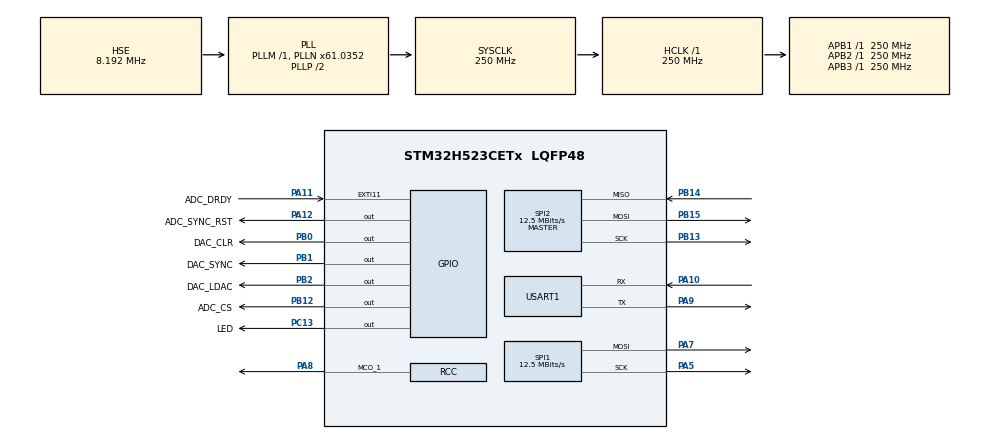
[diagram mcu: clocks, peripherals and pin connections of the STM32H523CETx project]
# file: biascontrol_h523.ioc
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BOOTPATH.BootPathName=LEGACY
BOOTPATH.UserSelectedBootPath=LEGACY
CORTEX_M33_NS.Number-Cortex_Memory_Protection_Unit_Region0_OTP_RO_AREAS_Settings=MPU_REGION_NUMBER0
CORTEX_M33_NS.default_mode_Activation=1
CORTEX_M33_NS.userName=CORTEX_M33
GPDMA1.CIRCULARMODE_GPDMACH4=ENABLE
GPDMA1.DESTINC_GPDMACH2=DMA_DINC_INCREMENTED
GPDMA1.DESTINC_GPDMACH4=DMA_DINC_INCREMENTED
GPDMA1.DIRECTION_GPDMACH0=DMA_MEMORY_TO_PERIPH
GPDMA1.DIRECTION_GPDMACH1=DMA_MEMORY_TO_PERIPH
GPDMA1.DIRECTION_GPDMACH3=DMA_MEMORY_TO_PERIPH
GPDMA1.IPHANDLE_GPDMACH0-SIMPLEREQUEST_GPDMACH0=__NULL
GPDMA1.IPHANDLE_GPDMACH1-SIMPLEREQUEST_GPDMACH1=__NULL
GPDMA1.IPHANDLE_GPDMACH2-SIMPLEREQUEST_GPDMACH2=__NULL
GPDMA1.IPHANDLE_GPDMACH3-SIMPLEREQUEST_GPDMACH3=__NULL
GPDMA1.IPHANDLE_GPDMACH4-SIMPLEREQUEST_GPDMACH4=__NULL
GPDMA1.LINKALLOCATEDPORT_CIRCULAR_GPDMACH4=DMA_LINK_ALLOCATED_PORT1
GPDMA1.REQUEST_GPDMACH0=GPDMA1_REQUEST_SPI1_TX
GPDMA1.REQUEST_GPDMACH1=GPDMA1_REQUEST_SPI2_TX
GPDMA1.REQUEST_GPDMACH2=GPDMA1_REQUEST_SPI2_RX
GPDMA1.REQUEST_GPDMACH3=GPDMA1_REQUEST_USART1_TX
GPDMA1.REQUEST_GPDMACH4=GPDMA1_REQUEST_USART1_RX
GPDMA1.SRCINC_GPDMACH0=DMA_SINC_INCREMENTED
GPDMA1.SRCINC_GPDMACH1=DMA_SINC_INCREMENTED
GPDMA1.SRCINC_GPDMACH3=DMA_SINC_INCREMENTED
GPDMA1.TRANSFERALLOCATEDPORTDEST_GPDMACH2=DMA_DEST_ALLOCATED_PORT1
GPDMA1.TRANSFERALLOCATEDPORTDEST_GPDMACH4=DMA_DEST_ALLOCATED_PORT1
GPDMA1.TRANSFERALLOCATEDPORTSRC_GPDMACH0=DMA_SRC_ALLOCATED_PORT1
GPDMA1.TRANSFERALLOCATEDPORTSRC_GPDMACH1=DMA_SRC_ALLOCATED_PORT1
GPDMA1.TRANSFERALLOCATEDPORTSRC_GPDMACH3=DMA_SRC_ALLOCATED_PORT1
Mcu.Family=STM32H5
Mcu.Name=STM32H523CETx
Mcu.Package=LQFP48
NVIC.EXTI11_IRQn=true\:0\:0\:false\:false\:true\:true\:true\:true
NVIC.GPDMA1_Channel0_IRQn=true\:3\:0\:true\:false\:true\:false\:true\:true
NVIC.GPDMA1_Channel1_IRQn=true\:2\:0\:true\:false\:true\:false\:true\:true
NVIC.GPDMA1_Channel2_IRQn=true\:2\:0\:true\:false\:true\:false\:true\:true
NVIC.GPDMA1_Channel3_IRQn=true\:5\:0\:true\:false\:true\:false\:true\:true
NVIC.GPDMA1_Channel4_IRQn=true\:5\:0\:true\:false\:true\:false\:true\:true
NVIC.PriorityGroup=NVIC_PRIORITYGROUP_4
NVIC.SPI1_IRQn=true\:4\:0\:true\:false\:true\:true\:true\:true
NVIC.SPI2_IRQn=true\:2\:0\:true\:false\:true\:true\:true\:true
NVIC.TIM6_IRQn=true\:6\:0\:true\:false\:true\:true\:true\:true
NVIC.USART1_IRQn=true\:5\:0\:true\:false\:true\:false\:true\:true
PA10.Mode=Asynchronous
PA10.Signal=USART1_RX
PA11.GPIO_Label=ADC_DRDY
PA11.GPIO_ModeDefaultEXTI=GPIO_MODE_IT_FALLING
PA11.GPIO_PuPd=GPIO_PULLUP
PA11.Signal=GPXTI11
PA12.GPIO_Label=ADC_SYNC_RST
PA12.GPIO_Speed=GPIO_SPEED_FREQ_VERY_HIGH
PA12.PinState=GPIO_PIN_SET
PA12.Signal=GPIO_Output
PA13(JTMS/SWDIO).Mode=Serial_Wire
PA13(JTMS/SWDIO).Signal=DEBUG_JTMS-SWDIO
PA14(JTCK/SWCLK).Mode=Serial_Wire
PA14(JTCK/SWCLK).Signal=DEBUG_JTCK-SWCLK
PA5.GPIO_Speed=GPIO_SPEED_FREQ_VERY_HIGH
PA5.Mode=TX_Only_Simplex_Unidirect_Master
PA5.Signal=SPI1_SCK
PA7.GPIO_Speed=GPIO_SPEED_FREQ_VERY_HIGH
PA7.Mode=TX_Only_Simplex_Unidirect_Master
PA7.Signal=SPI1_MOSI
PA8.Mode=Clock-out
PA8.Signal=RCC_MCO_1
PA9.Mode=Asynchronous
PA9.Signal=USART1_TX
PB0.GPIO_Label=DAC_CLR
PB0.GPIO_Speed=GPIO_SPEED_FREQ_VERY_HIGH
PB0.PinState=GPIO_PIN_SET
PB0.Signal=GPIO_Output
PB1.GPIO_Label=DAC_SYNC
PB1.GPIO_Speed=GPIO_SPEED_FREQ_VERY_HIGH
PB1.PinState=GPIO_PIN_SET
PB1.Signal=GPIO_Output
PB12.GPIO_Label=ADC_CS
PB12.GPIO_Speed=GPIO_SPEED_FREQ_VERY_HIGH
PB12.PinState=GPIO_PIN_SET
PB12.Signal=GPIO_Output
PB13.GPIO_Speed=GPIO_SPEED_FREQ_VERY_HIGH
PB13.Mode=Full_Duplex_Master
PB13.Signal=SPI2_SCK
PB14.GPIO_Speed=GPIO_SPEED_FREQ_VERY_HIGH
PB14.Mode=Full_Duplex_Master
PB14.Signal=SPI2_MISO
PB15.GPIO_Speed=GPIO_SPEED_FREQ_VERY_HIGH
PB15.Mode=Full_Duplex_Master
PB15.Signal=SPI2_MOSI
PB2.GPIO_Label=DAC_LDAC
PB2.GPIO_Speed=GPIO_SPEED_FREQ_VERY_HIGH
PB2.PinState=GPIO_PIN_SET
PB2.Signal=GPIO_Output
PC13.GPIO_Label=LED
PC13.Signal=GPIO_Output
PH0-OSC_IN(PH0).Mode=HSE-External-Oscillator
PH0-OSC_IN(PH0).Signal=RCC_OSC_IN
PH1-OSC_OUT(PH1).Mode=HSE-External-Oscillator
PH1-OSC_OUT(PH1).Signal=RCC_OSC_OUT
ProjectManager.HeapSize=0x800
ProjectManager.StackSize=0x1000
ProjectManager.TargetToolchain=Makefile
RCC.ADCFreq_Value=250000000
RCC.AHBFreq_Value=250000000
RCC.APB1Freq_Value=250000000
RCC.APB1TimFreq_Value=250000000
RCC.APB2Freq_Value=250000000
RCC.APB2TimFreq_Value=250000000
RCC.APB3Freq_Value=250000000
RCC.CSI_VALUE=4000000
RCC.CortexFreq_Value=250000000
RCC.EPOD_VALUE=8192000
RCC.HCLKFreq_Value=250000000
RCC.HSE_VALUE=8192000
RCC.HSI48_VALUE=48000000
RCC.HSI_VALUE=64000000
RCC.LSE_VALUE=32768
RCC.LSIRC_VALUE=32000
RCC.PLL1Q=5
RCC.PLL2Source=RCC_PLL2_SOURCE_HSE
RCC.PLL3Source=RCC_PLL3_SOURCE_HSE
RCC.PLLFRACN=288
RCC.PLLN=61
RCC.PLLSourceVirtual=RCC_PLL1_SOURCE_HSE
RCC.RCC_MCO1Source=RCC_MCO1SOURCE_HSE
RCC.SYSCLKFreq_VALUE=250000000
RCC.SYSCLKSource=RCC_SYSCLKSOURCE_PLLCLK
RCC.USBFreq_Value=48000000
RCC.VCOOutputFreq_Value=500000000
SPI1.BaudRatePrescaler=SPI_BAUDRATEPRESCALER_8
SPI1.CLKPhase=SPI_PHASE_2EDGE
SPI1.CalculateBaudRate=12.5 MBits/s
SPI1.DataSize=SPI_DATASIZE_8BIT
SPI1.Direction=SPI_DIRECTION_2LINES_TXONLY
SPI1.Mode=SPI_MODE_MASTER
SPI1.VirtualType=VM_MASTER
SPI2.BaudRatePrescaler=SPI_BAUDRATEPRESCALER_8
SPI2.CLKPhase=SPI_PHASE_2EDGE
SPI2.CalculateBaudRate=12.5 MBits/s
SPI2.DataSize=SPI_DATASIZE_8BIT
SPI2.Direction=SPI_DIRECTION_2LINES
SPI2.Mode=SPI_MODE_MASTER
SPI2.VirtualType=VM_MASTER
TIM6.AutoReloadPreload=TIM_AUTORELOAD_PRELOAD_ENABLE
TIM6.PeriodNoDither=999
TIM6.Prescaler=2499
USART1.VirtualMode-Asynchronous=VM_ASYNC
VP_BOOTPATH_VS_BOOTPATH.Mode=BP_Activate
VP_CORTEX_M33_NS_VS_Hclk.Mode=Hclk_Mode
VP_GPDMA1_VS_GPDMACH0.Mode=SIMPLEREQUEST_GPDMACH0
VP_GPDMA1_VS_GPDMACH1.Mode=SIMPLEREQUEST_GPDMACH1
VP_GPDMA1_VS_GPDMACH2.Mode=SIMPLEREQUEST_GPDMACH2
VP_GPDMA1_VS_GPDMACH3.Mode=SIMPLEREQUEST_GPDMACH3
VP_GPDMA1_VS_GPDMACH4.Mode=SIMPLEREQUEST_GPDMACH4
VP_ICACHE_VS_ICACHE.Mode=DirectMappedCache
VP_MEMORYMAP_VS_MEMORYMAP.Mode=CurAppReg
VP_PWR_VS_LPOM.Mode=PowerOptimisation
VP_PWR_VS_SECSignals.Mode=Security/Privilege
VP_TIM6_VS_ClockSourceINT.Mode=Enable_Timer
board=custom

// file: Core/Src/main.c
/* USER CODE BEGIN Header */
/**
  ******************************************************************************
  * @file           : main.c
  * @brief          : Main program body
  ******************************************************************************
  * @attention
  *
  * Copyright (c) 2026 STMicroelectronics.
  * All rights reserved.
  *
  * This software is licensed under terms that can be found in the LICENSE file
  * in the root directory of this software component.
  * If no LICENSE file comes with this software, it is provided AS-IS.
  *
  ******************************************************************************
  */
/* USER CODE END Header */
#include "main.h"
#include "gpdma.h"
#include "icache.h"
#include "spi.h"
#include "tim.h"
#include "usart.h"
#include "gpio.h"

/* USER CODE BEGIN Includes */
#include "app_main.h"
/* USER CODE END Includes */

void SystemClock_Config(void);
static void MPU_Config(void);

int main(void)
{

  /* MCU Configuration--------------------------------------------------------*/

  /* MPU Configuration--------------------------------------------------------*/
  MPU_Config();

  /* Reset of all peripherals, Initializes the Flash interface and the Systick. */
  HAL_Init();

  /* Configure the system clock */
  SystemClock_Config();

  /* Initialize all configured peripherals */
  MX_GPIO_Init();
  MX_GPDMA1_Init();
  MX_ICACHE_Init();
  MX_SPI1_Init();
  MX_SPI2_Init();
  MX_TIM6_Init();
  MX_USART1_UART_Init();
  /* USER CODE BEGIN 2 */
  app_init();
  /* USER CODE END 2 */

  /* Infinite loop */
  while (1)
  {

    /* USER CODE BEGIN 3 */
    app_run();
    __WFI();
  }
  /* USER CODE END 3 */
}

void SystemClock_Config(void)
{
  RCC_OscInitTypeDef RCC_OscInitStruct = {0};
  RCC_ClkInitTypeDef RCC_ClkInitStruct = {0};

  /** Configure the main internal regulator output voltage
  */
  __HAL_PWR_VOLTAGESCALING_CONFIG(PWR_REGULATOR_VOLTAGE_SCALE0);

  while(!__HAL_PWR_GET_FLAG(PWR_FLAG_VOSRDY)) {}

  /** Initializes the RCC Oscillators according to the specified parameters
  * in the RCC_OscInitTypeDef structure.
  */
  RCC_OscInitStruct.OscillatorType = RCC_OSCILLATORTYPE_HSE;
  RCC_OscInitStruct.HSEState = RCC_HSE_ON;
  RCC_OscInitStruct.PLL.PLLState = RCC_PLL_ON;
  RCC_OscInitStruct.PLL.PLLSource = RCC_PLL1_SOURCE_HSE;
  RCC_OscInitStruct.PLL.PLLM = 1;
  RCC_OscInitStruct.PLL.PLLN = 61;
  RCC_OscInitStruct.PLL.PLLP = 2;
  RCC_OscInitStruct.PLL.PLLQ = 5;
  RCC_OscInitStruct.PLL.PLLR = 2;
  RCC_OscInitStruct.PLL.PLLRGE = RCC_PLL1_VCIRANGE_3;
  RCC_OscInitStruct.PLL.PLLVCOSEL = RCC_PLL1_VCORANGE_WIDE;
  RCC_OscInitStruct.PLL.PLLFRACN = 288;
  if (HAL_RCC_OscConfig(&RCC_OscInitStruct) != HAL_OK)
  {
    Error_Handler();
  }

  /** Initializes the CPU, AHB and APB buses clocks
  */
  RCC_ClkInitStruct.ClockType = RCC_CLOCKTYPE_HCLK|RCC_CLOCKTYPE_SYSCLK
                              |RCC_CLOCKTYPE_PCLK1|RCC_CLOCKTYPE_PCLK2
                              |RCC_CLOCKTYPE_PCLK3;
  RCC_ClkInitStruct.SYSCLKSource = RCC_SYSCLKSOURCE_PLLCLK;
  RCC_ClkInitStruct.AHBCLKDivider = RCC_SYSCLK_DIV1;
  RCC_ClkInitStruct.APB1CLKDivider = RCC_HCLK_DIV1;
  RCC_ClkInitStruct.APB2CLKDivider = RCC_HCLK_DIV1;
  RCC_ClkInitStruct.APB3CLKDivider = RCC_HCLK_DIV1;

  if (HAL_RCC_ClockConfig(&RCC_ClkInitStruct, FLASH_LATENCY_5) != HAL_OK)
  {
    Error_Handler();
  }
  HAL_RCC_MCOConfig(RCC_MCO1, RCC_MCO1SOURCE_HSE, RCC_MCODIV_1);

  /** Configure the programming delay
  */
  __HAL_FLASH_SET_PROGRAM_DELAY(FLASH_PROGRAMMING_DELAY_2);
}

 /* MPU Configuration */

void MPU_Config(void)
{
  MPU_Region_InitTypeDef MPU_InitStruct = {0};
  MPU_Attributes_InitTypeDef MPU_AttributesInit = {0};

  /* Disables the MPU */
  HAL_MPU_Disable();

  /** Initializes and configures the Region 0 and the memory to be protected
  */
  MPU_InitStruct.Enable = MPU_REGION_ENABLE;
  MPU_InitStruct.Number = MPU_REGION_NUMBER0;
  MPU_InitStruct.BaseAddress = 0x08FFF000;
  MPU_InitStruct.LimitAddress = 0x08FFFFFF;
  MPU_InitStruct.AttributesIndex = MPU_ATTRIBUTES_NUMBER0;
  MPU_InitStruct.AccessPermission = MPU_REGION_ALL_RO;
  MPU_InitStruct.DisableExec = MPU_INSTRUCTION_ACCESS_DISABLE;
  MPU_InitStruct.IsShareable = MPU_ACCESS_NOT_SHAREABLE;

  HAL_MPU_ConfigRegion(&MPU_InitStruct);

  /** Initializes and configures the Attribute 0 and the memory to be protected
  */
  MPU_AttributesInit.Number = MPU_ATTRIBUTES_NUMBER0;
  MPU_AttributesInit.Attributes = INNER_OUTER(MPU_NOT_CACHEABLE);

  HAL_MPU_ConfigMemoryAttributes(&MPU_AttributesInit);
  /* Enables the MPU */
  HAL_MPU_Enable(MPU_PRIVILEGED_DEFAULT);

}

void Error_Handler(void)
{
  __disable_irq();
  while (1)
  {
  }
}
